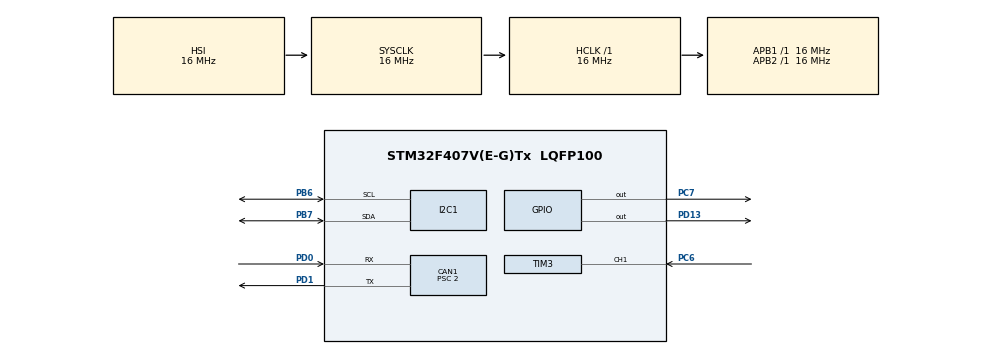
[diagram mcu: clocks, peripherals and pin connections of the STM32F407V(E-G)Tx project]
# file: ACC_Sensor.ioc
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CAN1.BS1=CAN_BS1_13TQ
CAN1.BS2=CAN_BS2_2TQ
CAN1.CalculateBaudRate=500000
CAN1.CalculateTimeBit=2000
CAN1.CalculateTimeQuantum=125.0
CAN1.Prescaler=2
I2C1.I2C_Mode=I2C_Fast
IWDG.Prescaler=IWDG_PRESCALER_32
IWDG.Reload=1000
Mcu.Family=STM32F4
Mcu.Name=STM32F407V(E-G)Tx
Mcu.Package=LQFP100
NVIC.CAN1_RX0_IRQn=true\:5\:0\:true\:false\:true\:true\:true\:true
NVIC.PriorityGroup=NVIC_PRIORITYGROUP_4
NVIC.TIM1_UP_TIM10_IRQn=true\:15\:0\:false\:false\:true\:false\:true\:true
NVIC.TIM3_IRQn=true\:5\:0\:true\:false\:true\:true\:true\:true
NVIC.TimeBase=TIM1_UP_TIM10_IRQn
NVIC.TimeBaseIP=TIM1
PB6.Mode=I2C
PB6.Signal=I2C1_SCL
PB7.Mode=I2C
PB7.Signal=I2C1_SDA
PC6.Signal=S_TIM3_CH1
PC7.Signal=GPIO_Output
PD0.Mode=CAN_Activate
PD0.Signal=CAN1_RX
PD1.Mode=CAN_Activate
PD1.Signal=CAN1_TX
PD13.Signal=GPIO_Output
ProjectManager.HeapSize=0x200
ProjectManager.StackSize=0x400
ProjectManager.TargetToolchain=STM32CubeIDE
RCC.AHBFreq_Value=16000000
RCC.APB1Freq_Value=16000000
RCC.APB2Freq_Value=16000000
RCC.CortexFreq_Value=16000000
RCC.HSE_VALUE=25000000
RCC.HSI_VALUE=16000000
RCC.LSE_VALUE=32768
RCC.SYSCLKFreq_VALUE=16000000
RCC.VCOOutputFreq_Value=192000000
SH.S_TIM3_CH1.0=TIM3_CH1,Input_Capture1_from_TI1
TIM3.Channel-Input_Capture1_from_TI1=TIM_CHANNEL_1
TIM3.ICPolarity_CH1=TIM_INPUTCHANNELPOLARITY_BOTHEDGE
TIM3.Prescaler=15
VP_IWDG_VS_IWDG.Mode=IWDG_Activate
VP_SYS_VS_tim1.Mode=TIM1
board=custom

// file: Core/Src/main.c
/* USER CODE BEGIN Header */
/**
  ******************************************************************************
  * @file           : main.c
  * @brief          : Main program body
  ******************************************************************************
  * @attention
  *
  * Copyright (c) 2026 STMicroelectronics.
  * All rights reserved.
  *
  * This software is licensed under terms that can be found in the LICENSE file
  * in the root directory of this software component.
  * If no LICENSE file comes with this software, it is provided AS-IS.
  *
  ******************************************************************************
  */
/* USER CODE END Header */
#include "main.h"

/* USER CODE BEGIN Includes */
#include "FreeRTOS.h"
#include "task.h"
#include "hcsr04_driver.h"
#include "can_driver.h"
#include "oled_display.h"
#include "app_tasks.h"
/* USER CODE END Includes */

CAN_HandleTypeDef hcan1;

I2C_HandleTypeDef hi2c1;

IWDG_HandleTypeDef hiwdg;

TIM_HandleTypeDef htim3;

void SystemClock_Config(void);
static void MX_GPIO_Init(void);
static void MX_CAN1_Init(void);
static void MX_I2C1_Init(void);
static void MX_IWDG_Init(void);
static void MX_TIM3_Init(void);

int main(void)
{

  /* MCU Configuration--------------------------------------------------------*/

  /* Reset of all peripherals, Initializes the Flash interface and the Systick. */
  HAL_Init();

  /* Configure the system clock */
  SystemClock_Config();

  /* Initialize all configured peripherals */
  MX_GPIO_Init();
  MX_CAN1_Init();
  MX_I2C1_Init();
  MX_IWDG_Init();
  MX_TIM3_Init();
  /* USER CODE BEGIN 2 */
  HCSR04_Init(&htim3);

  if (CANDRV_Init(&hcan1) != HAL_OK) { Error_Handler(); }

  if (OLED_Init(&hi2c1) != HAL_OK) { Error_Handler(); }

  if (!APP_Tasks_Init()) { Error_Handler(); }

  vTaskStartScheduler();

  /* USER CODE END 2 */

  /* Infinite loop */
  while (1)
  {

  }
}

void SystemClock_Config(void)
{
  RCC_OscInitTypeDef RCC_OscInitStruct = {0};
  RCC_ClkInitTypeDef RCC_ClkInitStruct = {0};

  /** Configure the main internal regulator output voltage
  */
  __HAL_RCC_PWR_CLK_ENABLE();
  __HAL_PWR_VOLTAGESCALING_CONFIG(PWR_REGULATOR_VOLTAGE_SCALE1);

  /** Initializes the RCC Oscillators according to the specified parameters
  * in the RCC_OscInitTypeDef structure.
  */
  RCC_OscInitStruct.OscillatorType = RCC_OSCILLATORTYPE_HSI|RCC_OSCILLATORTYPE_LSI;
  RCC_OscInitStruct.HSIState = RCC_HSI_ON;
  RCC_OscInitStruct.HSICalibrationValue = RCC_HSICALIBRATION_DEFAULT;
  RCC_OscInitStruct.LSIState = RCC_LSI_ON;
  RCC_OscInitStruct.PLL.PLLState = RCC_PLL_NONE;
  if (HAL_RCC_OscConfig(&RCC_OscInitStruct) != HAL_OK)
  {
    Error_Handler();
  }

  /** Initializes the CPU, AHB and APB buses clocks
  */
  RCC_ClkInitStruct.ClockType = RCC_CLOCKTYPE_HCLK|RCC_CLOCKTYPE_SYSCLK
                              |RCC_CLOCKTYPE_PCLK1|RCC_CLOCKTYPE_PCLK2;
  RCC_ClkInitStruct.SYSCLKSource = RCC_SYSCLKSOURCE_HSI;
  RCC_ClkInitStruct.AHBCLKDivider = RCC_SYSCLK_DIV1;
  RCC_ClkInitStruct.APB1CLKDivider = RCC_HCLK_DIV1;
  RCC_ClkInitStruct.APB2CLKDivider = RCC_HCLK_DIV1;

  if (HAL_RCC_ClockConfig(&RCC_ClkInitStruct, FLASH_LATENCY_0) != HAL_OK)
  {
    Error_Handler();
  }
}

static void MX_CAN1_Init(void)
{

  hcan1.Instance = CAN1;
  hcan1.Init.Prescaler = 2;
  hcan1.Init.Mode = CAN_MODE_NORMAL;
  hcan1.Init.SyncJumpWidth = CAN_SJW_1TQ;
  hcan1.Init.TimeSeg1 = CAN_BS1_13TQ;
  hcan1.Init.TimeSeg2 = CAN_BS2_2TQ;
  hcan1.Init.TimeTriggeredMode = DISABLE;
  hcan1.Init.AutoBusOff = DISABLE;
  hcan1.Init.AutoWakeUp = DISABLE;
  hcan1.Init.AutoRetransmission = DISABLE;
  hcan1.Init.ReceiveFifoLocked = DISABLE;
  hcan1.Init.TransmitFifoPriority = DISABLE;
  if (HAL_CAN_Init(&hcan1) != HAL_OK)
  {
    Error_Handler();
  }

}

static void MX_I2C1_Init(void)
{

  hi2c1.Instance = I2C1;
  hi2c1.Init.ClockSpeed = 400000;
  hi2c1.Init.DutyCycle = I2C_DUTYCYCLE_2;
  hi2c1.Init.OwnAddress1 = 0;
  hi2c1.Init.AddressingMode = I2C_ADDRESSINGMODE_7BIT;
  hi2c1.Init.DualAddressMode = I2C_DUALADDRESS_DISABLE;
  hi2c1.Init.OwnAddress2 = 0;
  hi2c1.Init.GeneralCallMode = I2C_GENERALCALL_DISABLE;
  hi2c1.Init.NoStretchMode = I2C_NOSTRETCH_DISABLE;
  if (HAL_I2C_Init(&hi2c1) != HAL_OK)
  {
    Error_Handler();
  }

}

static void MX_IWDG_Init(void)
{

  hiwdg.Instance = IWDG;
  hiwdg.Init.Prescaler = IWDG_PRESCALER_32;
  hiwdg.Init.Reload = 1000;
  if (HAL_IWDG_Init(&hiwdg) != HAL_OK)
  {
    Error_Handler();
  }

}

static void MX_TIM3_Init(void)
{

  TIM_MasterConfigTypeDef sMasterConfig = {0};
  TIM_IC_InitTypeDef sConfigIC = {0};

  htim3.Instance = TIM3;
  htim3.Init.Prescaler = 15;
  htim3.Init.CounterMode = TIM_COUNTERMODE_UP;
  htim3.Init.Period = 65535;
  htim3.Init.ClockDivision = TIM_CLOCKDIVISION_DIV1;
  htim3.Init.AutoReloadPreload = TIM_AUTORELOAD_PRELOAD_DISABLE;
  if (HAL_TIM_IC_Init(&htim3) != HAL_OK)
  {
    Error_Handler();
  }
  sMasterConfig.MasterOutputTrigger = TIM_TRGO_RESET;
  sMasterConfig.MasterSlaveMode = TIM_MASTERSLAVEMODE_DISABLE;
  if (HAL_TIMEx_MasterConfigSynchronization(&htim3, &sMasterConfig) != HAL_OK)
  {
    Error_Handler();
  }
  sConfigIC.ICPolarity = TIM_INPUTCHANNELPOLARITY_BOTHEDGE;
  sConfigIC.ICSelection = TIM_ICSELECTION_DIRECTTI;
  sConfigIC.ICPrescaler = TIM_ICPSC_DIV1;
  sConfigIC.ICFilter = 0;
  if (HAL_TIM_IC_ConfigChannel(&htim3, &sConfigIC, TIM_CHANNEL_1) != HAL_OK)
  {
    Error_Handler();
  }

}

static void MX_GPIO_Init(void)
{
  GPIO_InitTypeDef GPIO_InitStruct = {0};

  /* GPIO Ports Clock Enable */
  __HAL_RCC_GPIOD_CLK_ENABLE();
  __HAL_RCC_GPIOC_CLK_ENABLE();
  __HAL_RCC_GPIOB_CLK_ENABLE();

  /*Configure GPIO pin Output Level */
  HAL_GPIO_WritePin(GPIOD, GPIO_PIN_13, GPIO_PIN_RESET);

  /*Configure GPIO pin Output Level */
  HAL_GPIO_WritePin(GPIOC, GPIO_PIN_7, GPIO_PIN_RESET);

  /*Configure GPIO pin : PD13 */
  GPIO_InitStruct.Pin = GPIO_PIN_13;
  GPIO_InitStruct.Mode = GPIO_MODE_OUTPUT_PP;
  GPIO_InitStruct.Pull = GPIO_NOPULL;
  GPIO_InitStruct.Speed = GPIO_SPEED_FREQ_LOW;
  HAL_GPIO_Init(GPIOD, &GPIO_InitStruct);

  /*Configure GPIO pin : PC7 */
  GPIO_InitStruct.Pin = GPIO_PIN_7;
  GPIO_InitStruct.Mode = GPIO_MODE_OUTPUT_PP;
  GPIO_InitStruct.Pull = GPIO_NOPULL;
  GPIO_InitStruct.Speed = GPIO_SPEED_FREQ_LOW;
  HAL_GPIO_Init(GPIOC, &GPIO_InitStruct);

}

void HAL_TIM_PeriodElapsedCallback(TIM_HandleTypeDef *htim)
{
  if (htim->Instance == TIM1)
  {
    HAL_IncTick();
  }
}

void Error_Handler(void)
{
  __disable_irq();
  while (1)
  {
  }
}

#ifdef  USE_FULL_ASSERT
/**
  * @brief  Reports the name of the source file and the source line number
  *         where the assert_param error has occurred.
  * @param  file: pointer to the source file name
  * @param  line: assert_param error line source number
  * @retval None
  */
void assert_failed(uint8_t *file, uint32_t line)
{
  /* USER CODE BEGIN 6 */

	(void)file;
	    (void)line;
	    __disable_irq();
	    while (1) { /* trap here on a HAL parameter assertion failure */ }
  /* User can add his own implementation to report the file name and line number,
     ex: printf("Wrong parameters value: file %s on line %d\r\n", file, line) */
  /* USER CODE END 6 */
}
#endif /* USE_FULL_ASSERT */
